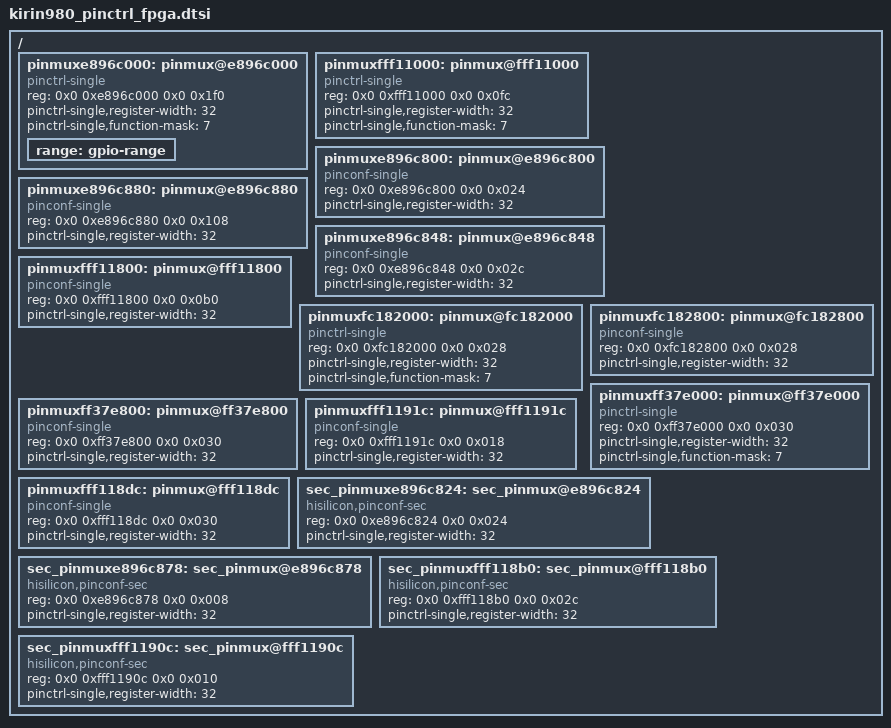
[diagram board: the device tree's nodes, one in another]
/*
 * Hisilicon Ltd. Kirin970_ES SoC
 *
 * Copyright (C) 2012-2014 Hisilicon Ltd.
 *
 * This program is free software; you can redistribute it and/or modify
 * it under the terms of the GNU General Public License version 2 as
 * publishhed by the Free Software Foundation.
 */

/ {
	pinmuxe896c000: pinmux@e896c000 {
		compatible = "pinctrl-single", "pinctrl-single0";
		reg = <0x0 0xe896c000 0x0 0x1f0>;
		#gpio-range-cells = <3>;
		//ranges;
		pinctrl-single,register-width = <32>;
		pinctrl-single,function-mask = <7>;
		/* pin base, nr pins & gpio function */
		//pinctrl-single,gpio-range = <&range 0 1 0 &range 2 5 0 &range 16 11 0 &range 30 17 0 &range 48 48 0>;
		range: gpio-range {
			#pinctrl-single,gpio-range-cells = <3>;
		};
	};

	pinmuxfff11000: pinmux@fff11000 {
		compatible = "pinctrl-single", "pinctrl-single1";
		reg = <0x0 0xfff11000 0x0 0x0fc>;
		#gpio-range-cells = <3>;
		//ranges;
		pinctrl-single,register-width = <32>;
		pinctrl-single,function-mask = <7>;
		/* pin base, nr pins & gpio function */
		//pinctrl-single,gpio-range = <&range 0 31 0 &range 42 11 0 &range 57 6 0>;
	};

	pinmuxe896c800: pinmux@e896c800 {
		compatible = "pinconf-single", "pinctrl-single2";
		reg = <0x0 0xe896c800 0x0 0x024>;
		pinctrl-single,register-width = <32>;
	};

	pinmuxe896c880: pinmux@e896c880 {
		compatible = "pinconf-single", "pinctrl-single3";
		reg = <0x0 0xe896c880 0x0 0x108>;
		pinctrl-single,register-width = <32>;
	};

	pinmuxe896c848: pinmux@e896c848 {
		compatible = "pinconf-single", "pinctrl-single4";
		reg = <0x0 0xe896c848 0x0 0x02c>;
		pinctrl-single,register-width = <32>;
	};

	pinmuxfff11800: pinmux@fff11800 {
		compatible = "pinconf-single", "pinctrl-single11";
		reg = <0x0 0xfff11800 0x0 0x0b0>;
		pinctrl-single,register-width = <32>;
	};

	pinmuxfc182000: pinmux@fc182000 {
		compatible = "pinctrl-single", "pinctrl-single5";
		reg = <0x0 0xfc182000 0x0 0x028>;
		#gpio-range-cells = <3>;
		pinctrl-single,register-width = <32>;
		pinctrl-single,function-mask = <7>;
		//pinctrl-single,gpio-range = <&range 0 10 0>;
	};

	pinmuxfc182800: pinmux@fc182800 {
		compatible = "pinconf-single", "pinctrl-single6";
		reg = <0x0 0xfc182800 0x0 0x028>;
		pinctrl-single,register-width = <32>;
	};

	pinmuxff37e000: pinmux@ff37e000 {
		compatible = "pinctrl-single", "pinctrl-single7";
		reg = <0x0 0xff37e000 0x0 0x030>;
		#gpio-range-cells = <3>;
		pinctrl-single,register-width = <32>;
		pinctrl-single,function-mask = <7>;
		/* pin base, nr pins & gpio function */
		//pinctrl-single,gpio-range = <&range 0 12 0>;
	};

	pinmuxff37e800: pinmux@ff37e800 {
		compatible = "pinconf-single", "pinctrl-single8";
		reg = <0x0 0xff37e800 0x0 0x030>;
		pinctrl-single,register-width = <32>;
	};

	pinmuxfff1191c: pinmux@fff1191c {
		compatible = "pinconf-single", "pinctrl-single9";
		reg = <0x0 0xfff1191c 0x0 0x018>;
		pinctrl-single,register-width = <32>;
	};

	pinmuxfff118dc: pinmux@fff118dc {
		compatible = "pinconf-single", "pinctrl-single10";
		reg = <0x0 0xfff118dc 0x0 0x030>;
		pinctrl-single,register-width = <32>;
	};

	sec_pinmuxe896c824: sec_pinmux@e896c824 {
		compatible = "hisilicon,pinconf-sec";
		reg = <0x0 0xe896c824 0x0 0x024>;
		pinctrl-single,register-width = <32>;
	};

	sec_pinmuxe896c878: sec_pinmux@e896c878 {
		compatible = "hisilicon,pinconf-sec";
		reg = <0x0 0xe896c878 0x0 0x008>;
		pinctrl-single,register-width = <32>;
	};

	sec_pinmuxfff118b0: sec_pinmux@fff118b0 {
		compatible = "hisilicon,pinconf-sec";
		reg = <0x0 0xfff118b0 0x0 0x02c>;
		pinctrl-single,register-width = <32>;
	};

	sec_pinmuxfff1190c: sec_pinmux@fff1190c {
		compatible = "hisilicon,pinconf-sec";
		reg = <0x0 0xfff1190c 0x0 0x010>;
		pinctrl-single,register-width = <32>;
	};
};
